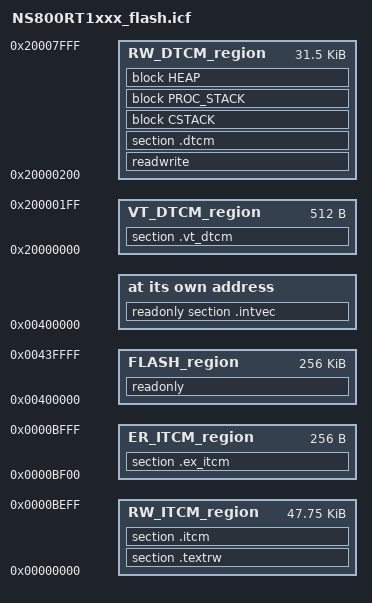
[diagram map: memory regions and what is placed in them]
/******************************************************************************
 * @file     NS800RT1xxx_flash.ld
 * @brief    IAR Linker Script for Cortex-M7 based device
 ******************************************************************************/
/*
 * Copyright 2025 Novosense Electronics. All rights reserved.
 */
/*-Specials-*/
define symbol __ICFEDIT_intvec_start__ = 0x00400000;
/*-Memory Regions-*/
define symbol __ICFEDIT_region_FLASH_start__   = 0x00400000;
define symbol __ICFEDIT_region_FLASH_end__     = 0x0043FFFF;
define symbol __ICFEDIT_region_RW_ITCM_start__ = 0x00000000;
define symbol __ICFEDIT_region_RW_ITCM_end__   = 0x0000BEFF;
define symbol __ICFEDIT_region_ER_ITCM_start__ = 0x0000BF00;
define symbol __ICFEDIT_region_ER_ITCM_end__   = 0x0000BFFF;
define symbol __ICFEDIT_region_VT_DTCM_start__ = 0x20000000;
define symbol __ICFEDIT_region_VT_DTCM_end__   = 0x200001FF;
define symbol __ICFEDIT_region_RW_DTCM_start__ = 0x20000200;
define symbol __ICFEDIT_region_RW_DTCM_end__   = 0x20007FFF;
/*-Sizes-*/
define symbol __ICFEDIT_size_cstack__          = 0x1000;
define symbol __ICFEDIT_size_proc_stack__      = 0x0;
define symbol __ICFEDIT_size_heap__            = 0x1000;

/**** End of ICF editor section. ###ICF###*/

define memory mem with size = 4G;
define region FLASH_region   =  mem:[from __ICFEDIT_region_FLASH_start__   to __ICFEDIT_region_FLASH_end__   ];
define region RW_ITCM_region =  mem:[from __ICFEDIT_region_RW_ITCM_start__ to __ICFEDIT_region_RW_ITCM_end__ ];
define region ER_ITCM_region =  mem:[from __ICFEDIT_region_ER_ITCM_start__ to __ICFEDIT_region_ER_ITCM_end__ ];
define region VT_DTCM_region =  mem:[from __ICFEDIT_region_VT_DTCM_start__ to __ICFEDIT_region_VT_DTCM_end__ ];
define region RW_DTCM_region =  mem:[from __ICFEDIT_region_RW_DTCM_start__ to __ICFEDIT_region_RW_DTCM_end__ ];

define block CSTACK     with alignment = 8, size = __ICFEDIT_size_cstack__     { };
define block PROC_STACK with alignment = 8, size = __ICFEDIT_size_proc_stack__ { };
define block HEAP       with alignment = 8, size = __ICFEDIT_size_heap__       { };

initialize by copy { readwrite, section .itcm, section .ex_itcm };
if (isdefinedsymbol(__USE_DLIB_PERTHREAD))
{
  // Required in a multi-threaded application
  initialize by copy with packing = none { section __DLIB_PERTHREAD };
}

do not initialize { section .noinit, section .VT_DTCM_region };

place at address mem:__ICFEDIT_intvec_start__ { readonly section .intvec };

place in FLASH_region   { readonly };
place in RW_ITCM_region { section .textrw, section .itcm};
place in ER_ITCM_region { section .ex_itcm};
place in VT_DTCM_region { section .vt_dtcm};
place in RW_DTCM_region { readwrite, section .dtcm, block CSTACK, block PROC_STACK, block HEAP};

